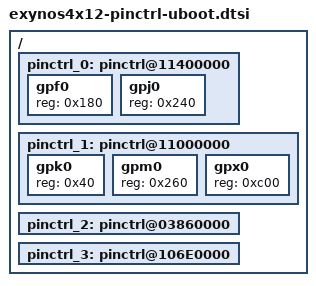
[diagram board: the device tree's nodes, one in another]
/*
 * U-Boot additions to enable a generic Exynos GPIO driver
 *
 * Copyright (c) 2014 Google, Inc
 *
 * SPDX-License-Identifier:	GPL-2.0+
 */

/{
	pinctrl_0: pinctrl@11400000 {
		#address-cells = <1>;
		#size-cells = <0>;
		gpf0: gpf0 {
			reg = <0x180>;
		};
		gpj0: gpj0 {
			reg = <0x240>;
		};
	};

	pinctrl_1: pinctrl@11000000 {
		#address-cells = <1>;
		#size-cells = <0>;
		gpk0: gpk0 {
			reg = <0x40>;
		};
		gpm0: gpm0 {
			reg = <0x260>;
		};
		gpx0: gpx0 {
			reg = <0xc00>;
		};
	};

	pinctrl_2: pinctrl@03860000 {
		#address-cells = <1>;
		#size-cells = <0>;
	};

	pinctrl_3: pinctrl@106E0000 {
		#address-cells = <1>;
		#size-cells = <0>;
	};

};
